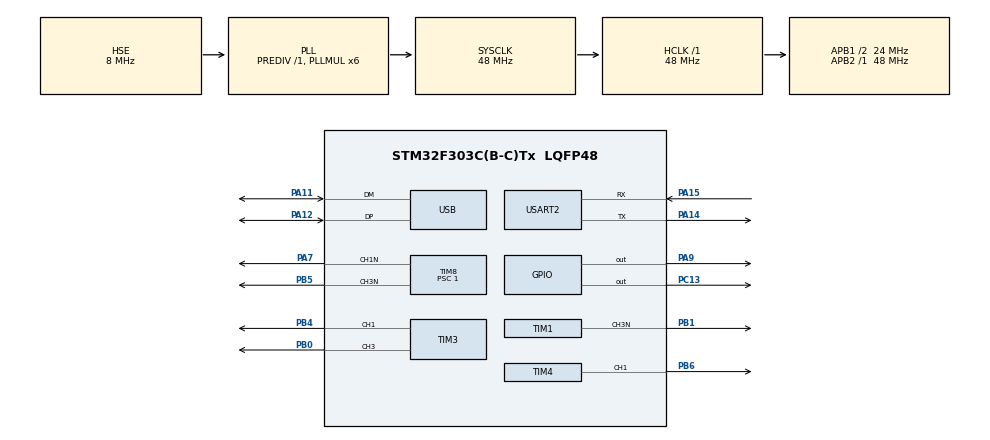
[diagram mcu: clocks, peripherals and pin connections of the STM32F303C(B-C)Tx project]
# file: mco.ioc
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Mcu.Family=STM32F3
Mcu.Name=STM32F303C(B-C)Tx
Mcu.Package=LQFP48
NVIC.PriorityGroup=NVIC_PRIORITYGROUP_4
NVIC.USB_LP_CAN_RX0_IRQn=true\:0\:0\:false\:false\:true\:false\:true\:true
PA11.Mode=Device
PA11.Signal=USB_DM
PA12.Mode=Device
PA12.Signal=USB_DP
PA14.Mode=Asynchronous
PA14.Signal=USART2_TX
PA15.Mode=Asynchronous
PA15.Signal=USART2_RX
PA7.Mode=PWM Generation1 CH1N
PA7.Signal=TIM8_CH1N
PA9.Signal=GPIO_Output
PB0.Signal=S_TIM3_CH3
PB1.Mode=PWM Generation3 CH3N
PB1.Signal=TIM1_CH3N
PB4.Signal=S_TIM3_CH1
PB5.Mode=PWM Generation3 CH3N
PB5.Signal=TIM8_CH3N
PB6.Signal=S_TIM4_CH1
PC13.Signal=GPIO_Output
PF0-OSC_IN.Mode=HSE-External-Oscillator
PF0-OSC_IN.Signal=RCC_OSC_IN
PF1-OSC_OUT.Mode=HSE-External-Oscillator
PF1-OSC_OUT.Signal=RCC_OSC_OUT
ProjectManager.HeapSize=0x200
ProjectManager.StackSize=0x400
ProjectManager.TargetToolchain=CMake
RCC.AHBFreq_Value=48000000
RCC.APB1CLKDivider=RCC_HCLK_DIV2
RCC.APB1Freq_Value=24000000
RCC.APB1TimFreq_Value=48000000
RCC.APB2Freq_Value=48000000
RCC.APB2TimFreq_Value=48000000
RCC.CortexFreq_Value=48000000
RCC.HCLKFreq_Value=48000000
RCC.HSE_VALUE=8000000
RCC.HSI_VALUE=8000000
RCC.LSE_VALUE=32768
RCC.PLLMUL=RCC_PLL_MUL6
RCC.SYSCLKFreq_VALUE=48000000
RCC.SYSCLKSourceVirtual=RCC_SYSCLKSOURCE_PLLCLK
RCC.USBFreq_Value=48000000
SH.S_TIM3_CH1.0=TIM3_CH1,PWM Generation1 CH1
SH.S_TIM3_CH3.0=TIM3_CH3,PWM Generation3 CH3
SH.S_TIM4_CH1.0=TIM4_CH1,PWM Generation1 CH1
TIM1.AutoReloadPreload=TIM_AUTORELOAD_PRELOAD_ENABLE
TIM1.Channel-PWM\ Generation3\ CH3N=TIM_CHANNEL_3
TIM1.ClockDivision=TIM_CLOCKDIVISION_DIV1
TIM1.CounterMode=TIM_COUNTERMODE_CENTERALIGNED1
TIM1.OCNPolarity_3=TIM_OCNPOLARITY_HIGH
TIM1.Period=65535
TIM1.Prescaler=1
TIM1.Pulse-PWM\ Generation3\ CH3N=21845
TIM1.RepetitionCounter=0
TIM3.AutoReloadPreload=TIM_AUTORELOAD_PRELOAD_ENABLE
TIM3.Channel-PWM\ Generation1\ CH1=TIM_CHANNEL_1
TIM3.Channel-PWM\ Generation3\ CH3=TIM_CHANNEL_3
TIM3.OCPolarity_1=TIM_OCPOLARITY_LOW
TIM3.Pulse-PWM\ Generation1\ CH1=43690
TIM3.Pulse-PWM\ Generation3\ CH3=21845
TIM4.AutoReloadPreload=TIM_AUTORELOAD_PRELOAD_ENABLE
TIM4.Channel-PWM\ Generation1\ CH1=TIM_CHANNEL_1
TIM4.CounterMode=TIM_COUNTERMODE_CENTERALIGNED1
TIM4.Pulse-PWM\ Generation1\ CH1=21845
TIM8.AutoReloadPreload=TIM_AUTORELOAD_PRELOAD_ENABLE
TIM8.Channel-PWM\ Generation1\ CH1N=TIM_CHANNEL_1
TIM8.Channel-PWM\ Generation3\ CH3N=TIM_CHANNEL_3
TIM8.ClockDivision=TIM_CLOCKDIVISION_DIV1
TIM8.OCNPolarity_3=TIM_OCNPOLARITY_LOW
TIM8.Prescaler=1
TIM8.Pulse-PWM\ Generation1\ CH1N=21845
TIM8.Pulse-PWM\ Generation3\ CH3N=43690
TIM8.RepetitionCounter=0
USART2.VirtualMode-Asynchronous=VM_ASYNC
USB_DEVICE.CLASS_NAME_FS=CDC
USB_DEVICE.VirtualMode=Cdc
USB_DEVICE.VirtualModeFS=Cdc_FS
VP_TIM1_VS_ClockSourceINT.Mode=Internal
VP_TIM3_VS_ClockSourceINT.Mode=Internal
VP_TIM4_VS_ClockSourceINT.Mode=Internal
VP_TIM8_VS_ClockSourceINT.Mode=Internal
VP_USB_DEVICE_VS_USB_DEVICE_CDC_FS.Mode=CDC_FS
board=custom

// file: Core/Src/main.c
/* USER CODE BEGIN Header */
/**
  ******************************************************************************
  * @file           : main.c
  * @brief          : Main program body
  ******************************************************************************
  * @attention
  *
  * Copyright (c) 2024 STMicroelectronics.
  * All rights reserved.
  *
  * This software is licensed under terms that can be found in the LICENSE file
  * in the root directory of this software component.
  * If no LICENSE file comes with this software, it is provided AS-IS.
  *
  ******************************************************************************
  */
/* USER CODE END Header */
#include "main.h"
#include "usb_device.h"

TIM_HandleTypeDef htim1;
TIM_HandleTypeDef htim3;
TIM_HandleTypeDef htim4;
TIM_HandleTypeDef htim8;

UART_HandleTypeDef huart2;

void SystemClock_Config(void);
static void MX_GPIO_Init(void);
static void MX_USART2_UART_Init(void);
static void MX_TIM1_Init(void);
static void MX_TIM8_Init(void);
static void MX_TIM3_Init(void);
static void MX_TIM4_Init(void);

int main(void)
{

  /* MCU Configuration--------------------------------------------------------*/

  /* Reset of all peripherals, Initializes the Flash interface and the Systick. */
  HAL_Init();

  /* Configure the system clock */
  SystemClock_Config();

  /* Initialize all configured peripherals */
  MX_GPIO_Init();
  MX_USART2_UART_Init();
  MX_USB_DEVICE_Init();
  MX_TIM1_Init();
  MX_TIM8_Init();
  MX_TIM3_Init();
  MX_TIM4_Init();
  /* USER CODE BEGIN 2 */
  HAL_GPIO_WritePin(GPIOA, GPIO_PIN_9, GPIO_PIN_SET);
  // PA7: U_SW
  HAL_TIMEx_PWMN_Start(&htim8, TIM_CHANNEL_1);
  // PB0: U_NSD
  HAL_TIM_PWM_Start(&htim3, TIM_CHANNEL_3);
  // PB1: V_SW
  HAL_TIMEx_PWMN_Start(&htim1, TIM_CHANNEL_3);
  // PB6: V_NSD
  HAL_TIM_PWM_Start(&htim4, TIM_CHANNEL_1);
  // PB5: W_SW
  HAL_TIMEx_PWMN_Start(&htim8, TIM_CHANNEL_3);
  // PB4: W_NSD
  HAL_TIM_PWM_Start(&htim3, TIM_CHANNEL_1);
  /* USER CODE END 2 */

  /* Infinite loop */
  /* USER CODE BEGIN WHILE */
  while (1)
  {
    HAL_GPIO_WritePin(GPIOC, GPIO_PIN_13, GPIO_PIN_SET);
    HAL_Delay(1000);
    HAL_GPIO_WritePin(GPIOC, GPIO_PIN_13, GPIO_PIN_RESET);
    HAL_Delay(1000);
    printf("Hi\r\n");
    /* USER CODE END WHILE */

  }
}

void SystemClock_Config(void)
{
  RCC_OscInitTypeDef RCC_OscInitStruct = {0};
  RCC_ClkInitTypeDef RCC_ClkInitStruct = {0};
  RCC_PeriphCLKInitTypeDef PeriphClkInit = {0};

  /** Initializes the RCC Oscillators according to the specified parameters
  * in the RCC_OscInitTypeDef structure.
  */
  RCC_OscInitStruct.OscillatorType = RCC_OSCILLATORTYPE_HSE;
  RCC_OscInitStruct.HSEState = RCC_HSE_ON;
  RCC_OscInitStruct.HSEPredivValue = RCC_HSE_PREDIV_DIV1;
  RCC_OscInitStruct.HSIState = RCC_HSI_ON;
  RCC_OscInitStruct.PLL.PLLState = RCC_PLL_ON;
  RCC_OscInitStruct.PLL.PLLSource = RCC_PLLSOURCE_HSE;
  RCC_OscInitStruct.PLL.PLLMUL = RCC_PLL_MUL6;
  if (HAL_RCC_OscConfig(&RCC_OscInitStruct) != HAL_OK)
  {
    Error_Handler();
  }

  /** Initializes the CPU, AHB and APB buses clocks
  */
  RCC_ClkInitStruct.ClockType = RCC_CLOCKTYPE_HCLK|RCC_CLOCKTYPE_SYSCLK
                              |RCC_CLOCKTYPE_PCLK1|RCC_CLOCKTYPE_PCLK2;
  RCC_ClkInitStruct.SYSCLKSource = RCC_SYSCLKSOURCE_PLLCLK;
  RCC_ClkInitStruct.AHBCLKDivider = RCC_SYSCLK_DIV1;
  RCC_ClkInitStruct.APB1CLKDivider = RCC_HCLK_DIV2;
  RCC_ClkInitStruct.APB2CLKDivider = RCC_HCLK_DIV1;

  if (HAL_RCC_ClockConfig(&RCC_ClkInitStruct, FLASH_LATENCY_1) != HAL_OK)
  {
    Error_Handler();
  }
  PeriphClkInit.PeriphClockSelection = RCC_PERIPHCLK_USB|RCC_PERIPHCLK_USART2
                              |RCC_PERIPHCLK_TIM1|RCC_PERIPHCLK_TIM8;
  PeriphClkInit.Usart2ClockSelection = RCC_USART2CLKSOURCE_PCLK1;
  PeriphClkInit.USBClockSelection = RCC_USBCLKSOURCE_PLL;
  PeriphClkInit.Tim1ClockSelection = RCC_TIM1CLK_HCLK;
  PeriphClkInit.Tim8ClockSelection = RCC_TIM8CLK_HCLK;
  if (HAL_RCCEx_PeriphCLKConfig(&PeriphClkInit) != HAL_OK)
  {
    Error_Handler();
  }
}

static void MX_TIM1_Init(void)
{

  /* USER CODE BEGIN TIM1_Init 0 */
  // INIT GPIO PINS
  // GPIO_InitTypeDef GPIO_InitStruct = {0};
  // GPIO_InitStruct.Pin = GPIO_PIN_0 | GPIO_PIN_1; // TIM1_CH1, TIM1_CH2, TIM1_CH3
  // GPIO_InitStruct.Mode = GPIO_MODE_AF_PP; // Alternate function push-pull
  // GPIO_InitStruct.Pull = GPIO_NOPULL;
  // GPIO_InitStruct.Speed = GPIO_SPEED_FREQ_LOW;
  // GPIO_InitStruct.Alternate = GPIO_AF2_TIM1; // Alternate function for TIM1
  // HAL_GPIO_Init(GPIOB, &GPIO_InitStruct);

  // GPIO_InitStruct.Pin = GPIO_PIN_7; // TIM1_CH1, TIM1_CH2, TIM1_CH3
  // HAL_GPIO_Init(GPIOA, &GPIO_InitStruct);

  /* USER CODE END TIM1_Init 0 */

  TIM_ClockConfigTypeDef sClockSourceConfig = {0};
  TIM_MasterConfigTypeDef sMasterConfig = {0};
  TIM_OC_InitTypeDef sConfigOC = {0};
  TIM_BreakDeadTimeConfigTypeDef sBreakDeadTimeConfig = {0};

  htim1.Instance = TIM1;
  htim1.Init.Prescaler = 1;
  htim1.Init.CounterMode = TIM_COUNTERMODE_CENTERALIGNED1;
  htim1.Init.Period = 65535;
  htim1.Init.ClockDivision = TIM_CLOCKDIVISION_DIV1;
  htim1.Init.RepetitionCounter = 0;
  htim1.Init.AutoReloadPreload = TIM_AUTORELOAD_PRELOAD_ENABLE;
  if (HAL_TIM_Base_Init(&htim1) != HAL_OK)
  {
    Error_Handler();
  }
  sClockSourceConfig.ClockSource = TIM_CLOCKSOURCE_INTERNAL;
  if (HAL_TIM_ConfigClockSource(&htim1, &sClockSourceConfig) != HAL_OK)
  {
    Error_Handler();
  }
  if (HAL_TIM_PWM_Init(&htim1) != HAL_OK)
  {
    Error_Handler();
  }
  sMasterConfig.MasterOutputTrigger = TIM_TRGO_RESET;
  sMasterConfig.MasterOutputTrigger2 = TIM_TRGO2_RESET;
  sMasterConfig.MasterSlaveMode = TIM_MASTERSLAVEMODE_DISABLE;
  if (HAL_TIMEx_MasterConfigSynchronization(&htim1, &sMasterConfig) != HAL_OK)
  {
    Error_Handler();
  }
  sConfigOC.OCMode = TIM_OCMODE_PWM1;
  sConfigOC.Pulse = 21845;
  sConfigOC.OCPolarity = TIM_OCPOLARITY_HIGH;
  sConfigOC.OCNPolarity = TIM_OCNPOLARITY_HIGH;
  sConfigOC.OCFastMode = TIM_OCFAST_DISABLE;
  sConfigOC.OCIdleState = TIM_OCIDLESTATE_RESET;
  sConfigOC.OCNIdleState = TIM_OCNIDLESTATE_RESET;
  if (HAL_TIM_PWM_ConfigChannel(&htim1, &sConfigOC, TIM_CHANNEL_3) != HAL_OK)
  {
    Error_Handler();
  }
  sBreakDeadTimeConfig.OffStateRunMode = TIM_OSSR_DISABLE;
  sBreakDeadTimeConfig.OffStateIDLEMode = TIM_OSSI_DISABLE;
  sBreakDeadTimeConfig.LockLevel = TIM_LOCKLEVEL_OFF;
  sBreakDeadTimeConfig.DeadTime = 0xFF;
  sBreakDeadTimeConfig.BreakState = TIM_BREAK_DISABLE;
  sBreakDeadTimeConfig.BreakPolarity = TIM_BREAKPOLARITY_HIGH;
  sBreakDeadTimeConfig.BreakFilter = 0;
  sBreakDeadTimeConfig.Break2State = TIM_BREAK2_DISABLE;
  sBreakDeadTimeConfig.Break2Polarity = TIM_BREAK2POLARITY_HIGH;
  sBreakDeadTimeConfig.Break2Filter = 0;
  sBreakDeadTimeConfig.AutomaticOutput = TIM_AUTOMATICOUTPUT_DISABLE;
  if (HAL_TIMEx_ConfigBreakDeadTime(&htim1, &sBreakDeadTimeConfig) != HAL_OK)
  {
    Error_Handler();
  }
  HAL_TIM_MspPostInit(&htim1);

}

static void MX_TIM3_Init(void)
{

  TIM_ClockConfigTypeDef sClockSourceConfig = {0};
  TIM_MasterConfigTypeDef sMasterConfig = {0};
  TIM_OC_InitTypeDef sConfigOC = {0};

  htim3.Instance = TIM3;
  htim3.Init.Prescaler = 0;
  htim3.Init.CounterMode = TIM_COUNTERMODE_UP;
  htim3.Init.Period = 65535;
  htim3.Init.ClockDivision = TIM_CLOCKDIVISION_DIV1;
  htim3.Init.AutoReloadPreload = TIM_AUTORELOAD_PRELOAD_ENABLE;
  if (HAL_TIM_Base_Init(&htim3) != HAL_OK)
  {
    Error_Handler();
  }
  sClockSourceConfig.ClockSource = TIM_CLOCKSOURCE_INTERNAL;
  if (HAL_TIM_ConfigClockSource(&htim3, &sClockSourceConfig) != HAL_OK)
  {
    Error_Handler();
  }
  if (HAL_TIM_PWM_Init(&htim3) != HAL_OK)
  {
    Error_Handler();
  }
  sMasterConfig.MasterOutputTrigger = TIM_TRGO_RESET;
  sMasterConfig.MasterSlaveMode = TIM_MASTERSLAVEMODE_DISABLE;
  if (HAL_TIMEx_MasterConfigSynchronization(&htim3, &sMasterConfig) != HAL_OK)
  {
    Error_Handler();
  }
  sConfigOC.OCMode = TIM_OCMODE_PWM1;
  sConfigOC.Pulse = 43690;
  sConfigOC.OCPolarity = TIM_OCPOLARITY_LOW;
  sConfigOC.OCFastMode = TIM_OCFAST_DISABLE;
  if (HAL_TIM_PWM_ConfigChannel(&htim3, &sConfigOC, TIM_CHANNEL_1) != HAL_OK)
  {
    Error_Handler();
  }
  sConfigOC.Pulse = 21845;
  sConfigOC.OCPolarity = TIM_OCPOLARITY_HIGH;
  if (HAL_TIM_PWM_ConfigChannel(&htim3, &sConfigOC, TIM_CHANNEL_3) != HAL_OK)
  {
    Error_Handler();
  }
  HAL_TIM_MspPostInit(&htim3);

}

static void MX_TIM4_Init(void)
{

  TIM_ClockConfigTypeDef sClockSourceConfig = {0};
  TIM_MasterConfigTypeDef sMasterConfig = {0};
  TIM_OC_InitTypeDef sConfigOC = {0};

  htim4.Instance = TIM4;
  htim4.Init.Prescaler = 0;
  htim4.Init.CounterMode = TIM_COUNTERMODE_CENTERALIGNED1;
  htim4.Init.Period = 65535;
  htim4.Init.ClockDivision = TIM_CLOCKDIVISION_DIV1;
  htim4.Init.AutoReloadPreload = TIM_AUTORELOAD_PRELOAD_ENABLE;
  if (HAL_TIM_Base_Init(&htim4) != HAL_OK)
  {
    Error_Handler();
  }
  sClockSourceConfig.ClockSource = TIM_CLOCKSOURCE_INTERNAL;
  if (HAL_TIM_ConfigClockSource(&htim4, &sClockSourceConfig) != HAL_OK)
  {
    Error_Handler();
  }
  if (HAL_TIM_PWM_Init(&htim4) != HAL_OK)
  {
    Error_Handler();
  }
  sMasterConfig.MasterOutputTrigger = TIM_TRGO_RESET;
  sMasterConfig.MasterSlaveMode = TIM_MASTERSLAVEMODE_DISABLE;
  if (HAL_TIMEx_MasterConfigSynchronization(&htim4, &sMasterConfig) != HAL_OK)
  {
    Error_Handler();
  }
  sConfigOC.OCMode = TIM_OCMODE_PWM1;
  sConfigOC.Pulse = 21845;
  sConfigOC.OCPolarity = TIM_OCPOLARITY_HIGH;
  sConfigOC.OCFastMode = TIM_OCFAST_DISABLE;
  if (HAL_TIM_PWM_ConfigChannel(&htim4, &sConfigOC, TIM_CHANNEL_1) != HAL_OK)
  {
    Error_Handler();
  }
  HAL_TIM_MspPostInit(&htim4);

}

static void MX_TIM8_Init(void)
{

  /* USER CODE BEGIN TIM8_Init 0 */
  // // INIT GPIO PINS
  // GPIO_InitTypeDef GPIO_InitStruct = {0};
  // GPIO_InitStruct.Pin = GPIO_PIN_6 | GPIO_PIN_5 | GPIO_PIN_4; // TIM1_CH1, TIM1_CH2, TIM1_CH3
  // GPIO_InitStruct.Mode = GPIO_MODE_AF_PP; // Alternate function push-pull
  // GPIO_InitStruct.Pull = GPIO_NOPULL;
  // GPIO_InitStruct.Speed = GPIO_SPEED_FREQ_LOW;
  // GPIO_InitStruct.Alternate = GPIO_AF2_TIM8; // Alternate function for TIM1
  // HAL_GPIO_Init(GPIOB, &GPIO_InitStruct);

  /* USER CODE END TIM8_Init 0 */

  TIM_ClockConfigTypeDef sClockSourceConfig = {0};
  TIM_MasterConfigTypeDef sMasterConfig = {0};
  TIM_OC_InitTypeDef sConfigOC = {0};
  TIM_BreakDeadTimeConfigTypeDef sBreakDeadTimeConfig = {0};

  htim8.Instance = TIM8;
  htim8.Init.Prescaler = 1;
  htim8.Init.CounterMode = TIM_COUNTERMODE_UP;
  htim8.Init.Period = 65535;
  htim8.Init.ClockDivision = TIM_CLOCKDIVISION_DIV1;
  htim8.Init.RepetitionCounter = 0;
  htim8.Init.AutoReloadPreload = TIM_AUTORELOAD_PRELOAD_ENABLE;
  if (HAL_TIM_Base_Init(&htim8) != HAL_OK)
  {
    Error_Handler();
  }
  sClockSourceConfig.ClockSource = TIM_CLOCKSOURCE_INTERNAL;
  if (HAL_TIM_ConfigClockSource(&htim8, &sClockSourceConfig) != HAL_OK)
  {
    Error_Handler();
  }
  if (HAL_TIM_PWM_Init(&htim8) != HAL_OK)
  {
    Error_Handler();
  }
  sMasterConfig.MasterOutputTrigger = TIM_TRGO_RESET;
  sMasterConfig.MasterOutputTrigger2 = TIM_TRGO2_RESET;
  sMasterConfig.MasterSlaveMode = TIM_MASTERSLAVEMODE_DISABLE;
  if (HAL_TIMEx_MasterConfigSynchronization(&htim8, &sMasterConfig) != HAL_OK)
  {
    Error_Handler();
  }
  sConfigOC.OCMode = TIM_OCMODE_PWM1;
  sConfigOC.Pulse = 21845;
  sConfigOC.OCPolarity = TIM_OCPOLARITY_HIGH;
  sConfigOC.OCNPolarity = TIM_OCNPOLARITY_HIGH;
  sConfigOC.OCFastMode = TIM_OCFAST_DISABLE;
  sConfigOC.OCIdleState = TIM_OCIDLESTATE_RESET;
  sConfigOC.OCNIdleState = TIM_OCNIDLESTATE_RESET;
  if (HAL_TIM_PWM_ConfigChannel(&htim8, &sConfigOC, TIM_CHANNEL_1) != HAL_OK)
  {
    Error_Handler();
  }
  sConfigOC.Pulse = 43690;
  sConfigOC.OCNPolarity = TIM_OCNPOLARITY_LOW;
  if (HAL_TIM_PWM_ConfigChannel(&htim8, &sConfigOC, TIM_CHANNEL_3) != HAL_OK)
  {
    Error_Handler();
  }
  sBreakDeadTimeConfig.OffStateRunMode = TIM_OSSR_DISABLE;
  sBreakDeadTimeConfig.OffStateIDLEMode = TIM_OSSI_DISABLE;
  sBreakDeadTimeConfig.LockLevel = TIM_LOCKLEVEL_OFF;
  sBreakDeadTimeConfig.DeadTime = 0xFF;
  sBreakDeadTimeConfig.BreakState = TIM_BREAK_DISABLE;
  sBreakDeadTimeConfig.BreakPolarity = TIM_BREAKPOLARITY_HIGH;
  sBreakDeadTimeConfig.BreakFilter = 0;
  sBreakDeadTimeConfig.Break2State = TIM_BREAK2_DISABLE;
  sBreakDeadTimeConfig.Break2Polarity = TIM_BREAK2POLARITY_HIGH;
  sBreakDeadTimeConfig.Break2Filter = 0;
  sBreakDeadTimeConfig.AutomaticOutput = TIM_AUTOMATICOUTPUT_DISABLE;
  if (HAL_TIMEx_ConfigBreakDeadTime(&htim8, &sBreakDeadTimeConfig) != HAL_OK)
  {
    Error_Handler();
  }
  HAL_TIM_MspPostInit(&htim8);

}

static void MX_USART2_UART_Init(void)
{

  huart2.Instance = USART2;
  huart2.Init.BaudRate = 38400;
  huart2.Init.WordLength = UART_WORDLENGTH_8B;
  huart2.Init.StopBits = UART_STOPBITS_1;
  huart2.Init.Parity = UART_PARITY_NONE;
  huart2.Init.Mode = UART_MODE_TX_RX;
  huart2.Init.HwFlowCtl = UART_HWCONTROL_NONE;
  huart2.Init.OverSampling = UART_OVERSAMPLING_16;
  huart2.Init.OneBitSampling = UART_ONE_BIT_SAMPLE_DISABLE;
  huart2.AdvancedInit.AdvFeatureInit = UART_ADVFEATURE_NO_INIT;
  if (HAL_UART_Init(&huart2) != HAL_OK)
  {
    Error_Handler();
  }

}

static void MX_GPIO_Init(void)
{
  GPIO_InitTypeDef GPIO_InitStruct = {0};

  /* GPIO Ports Clock Enable */
  __HAL_RCC_GPIOC_CLK_ENABLE();
  __HAL_RCC_GPIOF_CLK_ENABLE();
  __HAL_RCC_GPIOA_CLK_ENABLE();
  __HAL_RCC_GPIOB_CLK_ENABLE();

  /*Configure GPIO pin Output Level */
  HAL_GPIO_WritePin(GPIOC, GPIO_PIN_13, GPIO_PIN_RESET);

  /*Configure GPIO pin Output Level */
  HAL_GPIO_WritePin(GPIOA, GPIO_PIN_9, GPIO_PIN_RESET);

  /*Configure GPIO pin : PC13 */
  GPIO_InitStruct.Pin = GPIO_PIN_13;
  GPIO_InitStruct.Mode = GPIO_MODE_OUTPUT_PP;
  GPIO_InitStruct.Pull = GPIO_NOPULL;
  GPIO_InitStruct.Speed = GPIO_SPEED_FREQ_LOW;
  HAL_GPIO_Init(GPIOC, &GPIO_InitStruct);

  /*Configure GPIO pin : PA9 */
  GPIO_InitStruct.Pin = GPIO_PIN_9;
  GPIO_InitStruct.Mode = GPIO_MODE_OUTPUT_PP;
  GPIO_InitStruct.Pull = GPIO_NOPULL;
  GPIO_InitStruct.Speed = GPIO_SPEED_FREQ_LOW;
  HAL_GPIO_Init(GPIOA, &GPIO_InitStruct);

}

void Error_Handler(void)
{
  __disable_irq();
  while (1)
  {
  }
}
